# ADSP-2183xW_LPC register map
Vendor: Analog Devices; Series: ADSP-2183xW_LPC; File version: 3.0.3.517
CPU: 
Registers are 32-bit, read-write, reset 0x0 unless marked. A register's access mark holds for its fields unless they carry their own. Offsets are from the block's base; [hi:lo] are bit positions; {n}, {i} and the like mark numbered series; 'fields as' and 'values as' point back to an identical list.

## DAI0 — The Digital Audio Interface (DAIn) registers are used to configure DAI destinations for the DAI sources shown in the Group A - F Routing tables.
Base 0x310C9000
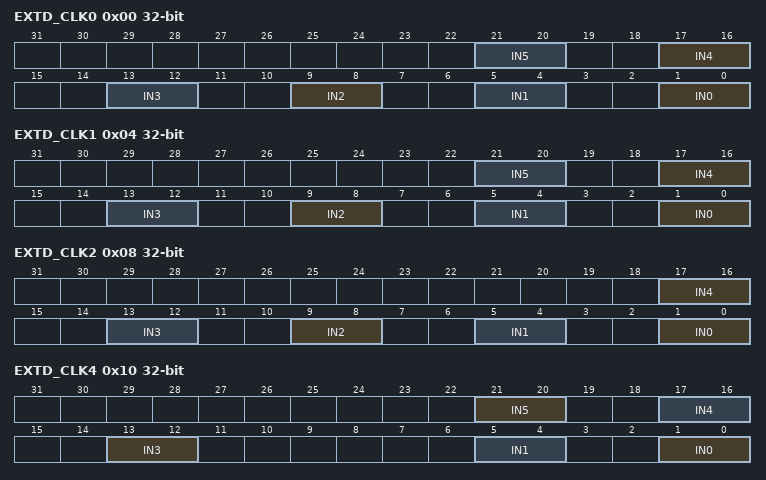
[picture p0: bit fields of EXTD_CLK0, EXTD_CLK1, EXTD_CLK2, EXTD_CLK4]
0x00 EXTD_CLK0 — Extended Clock Routing Control Register 0
  [4n+1:4n] IN{n} range 0x00000000..0x00000003 (n=0..5) — Extended Input Clock {n}
0x04 EXTD_CLK1 — Extended Clock Routing Control Register 1
  fields as EXTD_CLK0
0x08 EXTD_CLK2 — Extended Clock Routing Control Register 2
  [4n+1:4n] IN{n} range 0x00000000..0x00000003 (n=0..4) — Extended Input Clock {n}
0x0C EXTD_CLK3 — Extended Clock Routing Control Register 3
  [21:20] IN5 range 0x00000000..0x00000003 — Extended Input Clock 0
0x10 EXTD_CLK4 — Extended Clock Routing Control Register 4
  [21:20] IN5 range 0x00000000..0x00000003 — Extended Input Clock 5
  [17:16] IN4 range 0x00000000..0x00000003 — Extended Input Clock 4
  [13:12] IN3 range 0x00000000..0x00000003 — Extended Input Clock 3
  [5:4] IN1 range 0x00000000..0x00000003 — Extended Input Clock 1
  [1:0] IN0 range 0x00000000..0x00000003 — Extended Input Clock 0
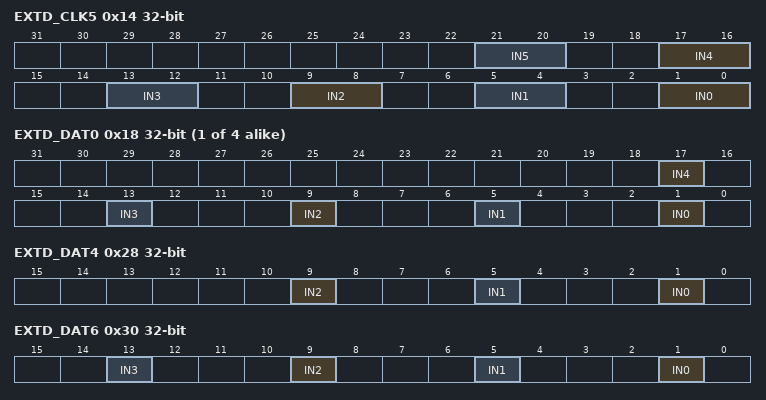
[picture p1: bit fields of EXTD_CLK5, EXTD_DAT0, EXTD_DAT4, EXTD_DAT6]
0x14 EXTD_CLK5 — Extended Clock Routing Control Register 5
  fields as EXTD_CLK0
{0x18+4i} EXTD_DAT{i} (i=0..3) — Extended Serial Data Routing Control Register {i}
  [4n+1] IN{n} range 0x00000000..0x00000001 (n=0..4) — Extended Input Data {n}
0x28 EXTD_DAT4 — Extended Serial Data Routing Control Register 4
  [9] IN2 range 0x00000000..0x00000001 — Extended Input Data 2
  [5] IN1 range 0x00000000..0x00000001 — Extended Input Data 1
  [1] IN0 range 0x00000000..0x00000001 — Extended Input Data 0
0x2C EXTD_DAT5 — Extended Serial Data Routing Control Register 5
  [17] IN4 range 0x00000000..0x00000001 — Extended Input Data 4
0x30 EXTD_DAT6 — Extended Serial Data Routing Control Register 6
  [4n+1] IN{n} range 0x00000000..0x00000001 (n=0..3) — Extended Input Data {n}
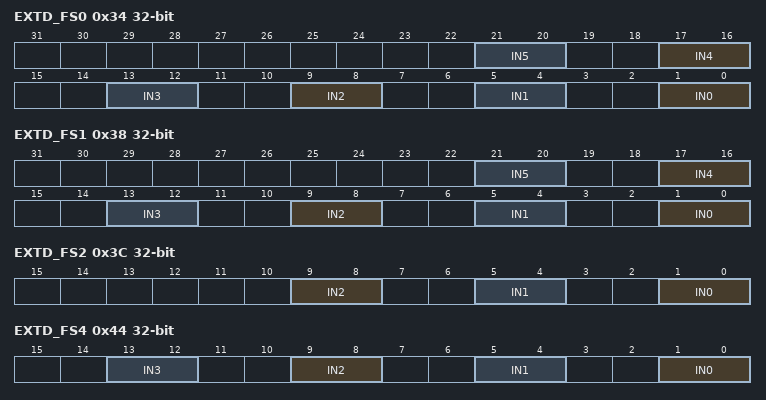
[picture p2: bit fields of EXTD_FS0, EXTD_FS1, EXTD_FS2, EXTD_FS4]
0x34 EXTD_FS0 — Extended Frame Sync Routing Control Register 0
  [4n+1:4n] IN{n} range 0x00000000..0x00000003 (n=0..5) — Extended Input Frame Sync {n}
0x38 EXTD_FS1 — Extended Frame Sync Routing Control Register 1
  fields as EXTD_FS0
0x3C EXTD_FS2 — Extended Frame Sync Routing Control Register 2
  [9:8] IN2 range 0x00000000..0x00000003 — Extended Input Frame Sync 2
  [5:4] IN1 range 0x00000000..0x00000003 — Extended Input Frame Sync 1
  [1:0] IN0 range 0x00000000..0x00000003 — Extended Input Frame Sync 0
0x44 EXTD_FS4 — Extended Frame Sync Routing Control Register 4
  [4n+1:4n] IN{n} range 0x00000000..0x00000003 (n=0..3) — Extended Input Frame Sync {n}
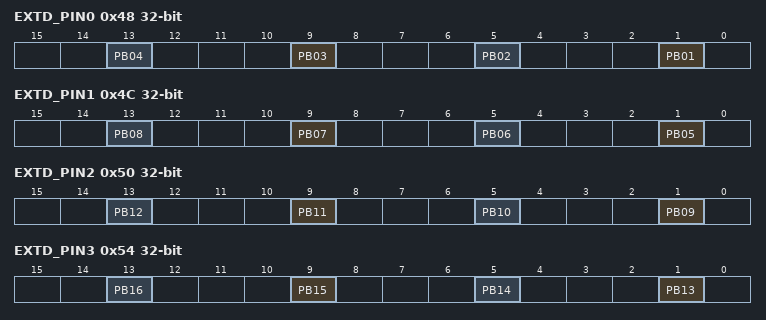
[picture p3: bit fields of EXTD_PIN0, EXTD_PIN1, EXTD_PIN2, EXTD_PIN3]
0x48 EXTD_PIN0 — Extended Pin Buffer Assignment Register 0
  [4n-3] PB{n:02} range 0x00000000..0x00000001 (n=1..4) — Extended Pin Buffer {n} Input
0x4C EXTD_PIN1 — Extended Pin Buffer Assignment Register 1
  [4n-19] PB{n:02} range 0x00000000..0x00000001 (n=5..8) — Extended Pin Buffer {n} Input
0x50 EXTD_PIN2 — Extended Pin Buffer Assignment Register 2
  [4n-35] PB{n:02} range 0x00000000..0x00000001 (n=9..12) — Extended Pin Buffer {n} Input
0x54 EXTD_PIN3 — Extended Pin Buffer Assignment Register 3
  [4n-51] PB{n} range 0x00000000..0x00000001 (n=13..16) — Extended Pin Buffer {n} Input
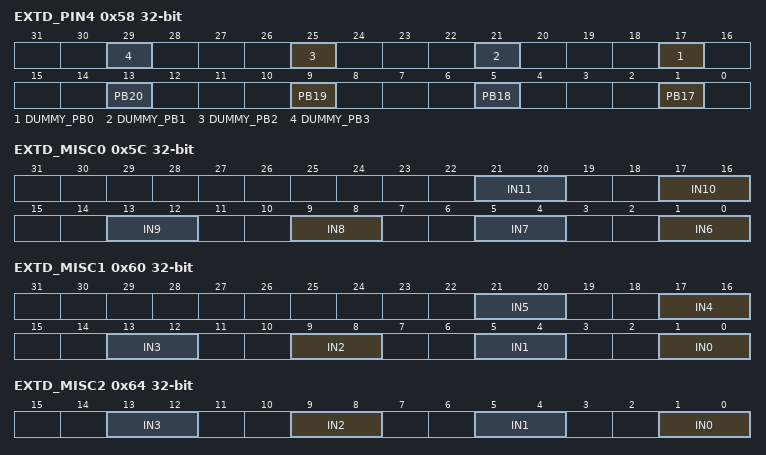
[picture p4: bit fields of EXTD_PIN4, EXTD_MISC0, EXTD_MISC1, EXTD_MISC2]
0x58 EXTD_PIN4 — Extended Pin Buffer Assignment Register 4
  [4n+17] DUMMY_PB{n} range 0x00000000..0x00000001 (n=0..3) — Extended Dummy Pin Buffer {n} Input
  [4n-67] PB{n} range 0x00000000..0x00000001 (n=17..20) — Extended Pin Buffer {n} Input
0x5C EXTD_MISC0 — Extended Miscellaneous Control Register 0
  [4n-23:4n-24] IN{n} range 0x00000000..0x00000003 (n=6..11) — Extended Input {n}
0x60 EXTD_MISC1 — Extended Miscellaneous Control Register 1
  [4n+1:4n] IN{n} range 0x00000000..0x00000003 (n=0..5) — Extended Input {n}
0x64 EXTD_MISC2 — Extended Miscellaneous Control Register 2
  [4n+1:4n] IN{n} range 0x00000000..0x00000003 (n=0..3) — Extended Input {n}
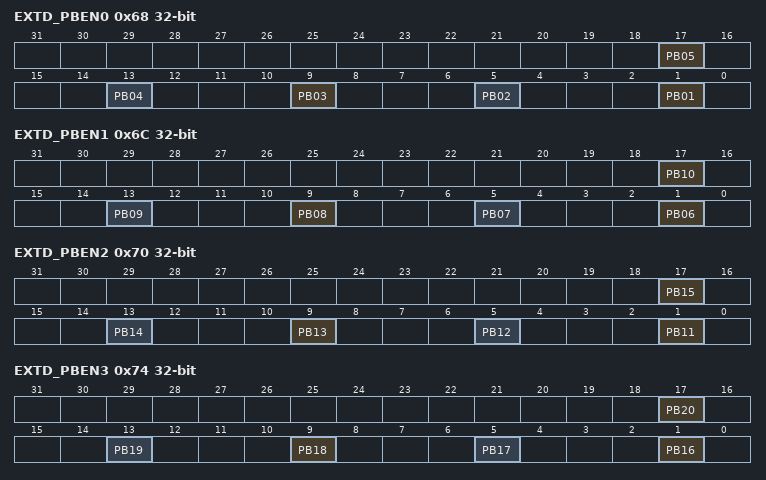
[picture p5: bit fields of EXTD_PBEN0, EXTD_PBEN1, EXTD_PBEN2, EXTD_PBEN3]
0x68 EXTD_PBEN0 — Extended Pin Buffer Enable Register 0
  [4n-3] PB{n:02} range 0x00000000..0x00000001 (n=1..5) — Extended Pin Buffer Enable {n}
0x6C EXTD_PBEN1 — Extended Pin Buffer Enable Register 1
  [4n-23] PB{n:02} range 0x00000000..0x00000001 (n=6..10) — Extended Pin Buffer Enable {n}
0x70 EXTD_PBEN2 — Extended Pin Buffer Enable Register 2
  [4n-43] PB{n} range 0x00000000..0x00000001 (n=11..15) — Extended Pin Buffer Enable {n}
0x74 EXTD_PBEN3 — Extended Pin Buffer Enable Register 3
  [4n-63] PB{n} range 0x00000000..0x00000001 (n=16..20) — Extended Pin Buffer Enable {n}
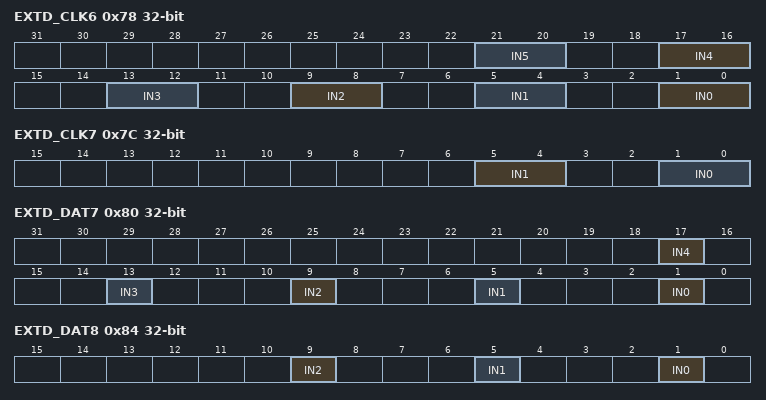
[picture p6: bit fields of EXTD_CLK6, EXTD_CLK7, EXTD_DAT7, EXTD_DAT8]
0x78 EXTD_CLK6 — Extended Clock Routing Control Register 6
  fields as EXTD_CLK0
0x7C EXTD_CLK7 — Extended Clock Routing Control Register 7
  [5:4] IN1 range 0x00000000..0x00000003 — Extended Input Clock 1
  [1:0] IN0 range 0x00000000..0x00000003 — Extended Input Clock 0
0x80 EXTD_DAT7 — Extended Serial Data Routing Control Register 7
  fields as EXTD_DAT0
0x84 EXTD_DAT8 — Extended Serial Data Routing Control Register 8
  fields as EXTD_DAT4
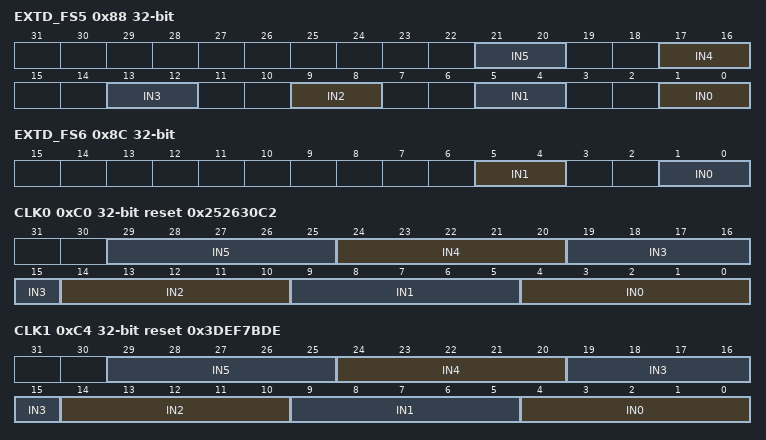
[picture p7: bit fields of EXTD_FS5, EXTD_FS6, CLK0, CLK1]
0x88 EXTD_FS5 — Extended Frame Sync Routing Control Register 5
  fields as EXTD_FS0
0x8C EXTD_FS6 — Extended Frame Sync Routing Control Register 6
  [5:4] IN1 range 0x00000000..0x00000003 — Extended Input Frame Sync 1
  [1:0] IN0 range 0x00000000..0x00000003 — Extended Input Frame Sync 0
0x9C DAI_MISC_CTL — DAI MISC Control Register
  [0] DUMMY_PAD_EN range 0x00000000..0x00000001 — Programmable Dummy Pad Enable
0xC0 CLK0 reset 0x252630C2 — Clock Routing Control Register 0
  [5n+4:5n] IN{n} range 0x00000000..0x0000001F (n=0..5) — Input Clock {n}
0xC4 CLK1 reset 0x3DEF7BDE — Clock Routing Control Register 1
  fields as CLK0
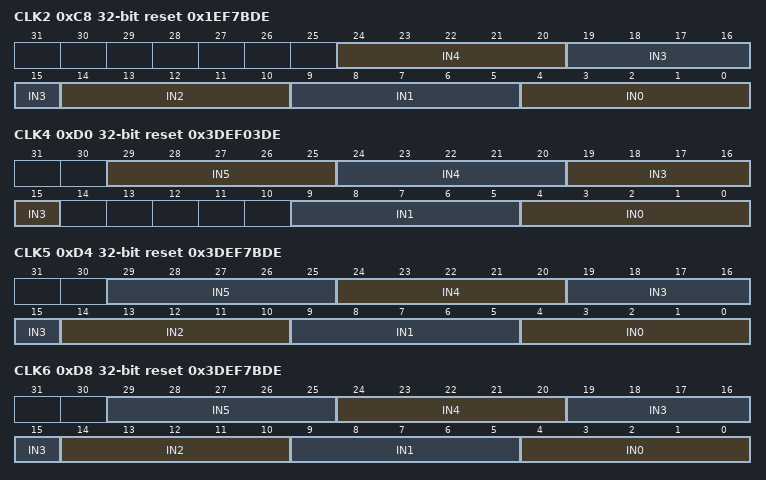
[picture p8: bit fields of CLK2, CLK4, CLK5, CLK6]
0xC8 CLK2 reset 0x1EF7BDE — Clock Routing Control Register 2
  [5n+4:5n] IN{n} range 0x00000000..0x0000001F (n=0..4) — Input Clock {n}
0xCC CLK3 reset 0x3C000000 — Clock Routing Control Register 3
  [29:25] IN5 range 0x00000000..0x0000001F — Input Clock 5
0xD0 CLK4 reset 0x3DEF03DE — Clock Routing Control Register 4
  [29:25] IN5 range 0x00000000..0x0000001F — Input Clock 5
  [24:20] IN4 range 0x00000000..0x0000001F — Input Clock 4
  [19:15] IN3 range 0x00000000..0x0000001F — Input Clock 3
  [9:5] IN1 range 0x00000000..0x0000001F — Input Clock 1
  [4:0] IN0 range 0x00000000..0x0000001F — Input Clock 0
0xD4 CLK5 reset 0x3DEF7BDE — Clock Routing Control Register 5
  fields as CLK0
0xD8 CLK6 reset 0x3DEF7BDE — Clock Routing Control Register 6
  fields as CLK0
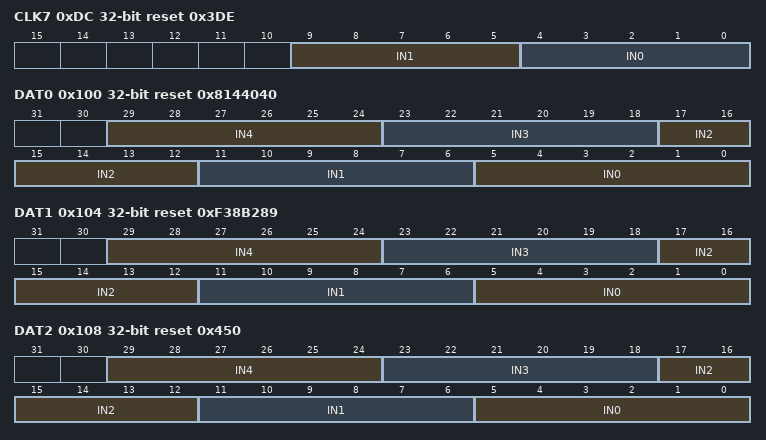
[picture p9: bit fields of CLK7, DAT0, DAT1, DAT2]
0xDC CLK7 reset 0x3DE — Clock Routing Control Register 7
  [9:5] IN1 range 0x00000000..0x0000001F — Input Clock 1
  [4:0] IN0 range 0x00000000..0x0000001F — Input Clock 0
0x100 DAT0 reset 0x8144040 — Serial Data Routing Control Register 0
  [6n+5:6n] IN{n} range 0x00000000..0x0000003F (n=0..4) — Input Data {n}
0x104 DAT1 reset 0xF38B289 — Serial Data Routing Control Register 1
  fields as DAT0
0x108 DAT2 reset 0x450 — Serial Data Routing Control Register 2
  fields as DAT0
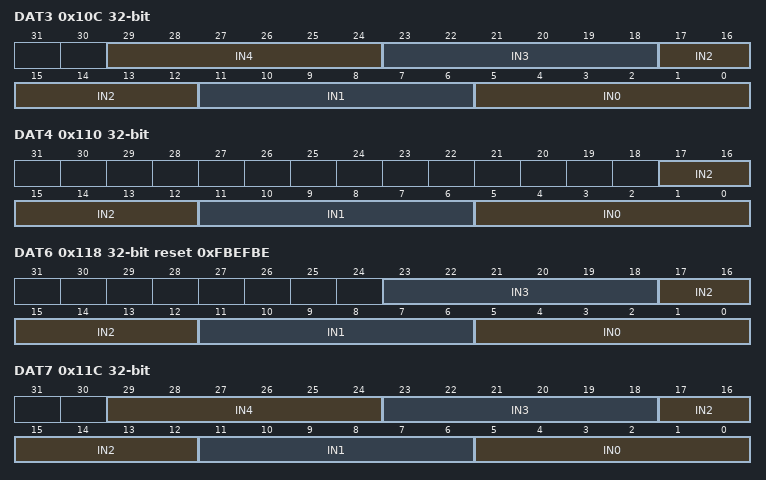
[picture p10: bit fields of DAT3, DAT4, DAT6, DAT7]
0x10C DAT3 — Serial Data Routing Control Register 3
  fields as DAT0
0x110 DAT4 — Serial Data Routing Control Register 4
  [17:12] IN2 range 0x00000000..0x0000003F — Input Data 2
  [11:6] IN1 range 0x00000000..0x0000003F — Input Data 1
  [5:0] IN0 range 0x00000000..0x0000003F — Input Data 0
0x114 DAT5 — Serial Data Routing Control Register 5
  [29:24] IN4 range 0x00000000..0x0000003F — Input Data 4
0x118 DAT6 reset 0xFBEFBE — Serial Data Routing Control Register 6
  [6n+5:6n] IN{n} range 0x00000000..0x0000003F (n=0..3) — Input Data {n}
0x11C DAT7 — Serial Data Routing Control Register 7
  fields as DAT0
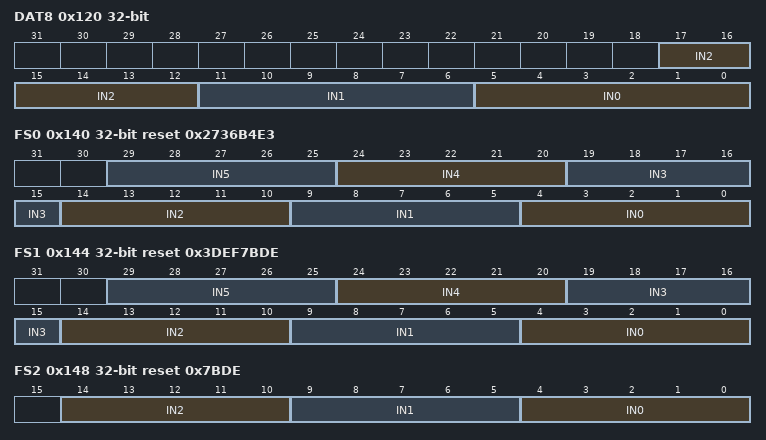
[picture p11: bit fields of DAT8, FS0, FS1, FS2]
0x120 DAT8 — Serial Data Routing Control Register 8
  fields as DAT4
0x140 FS0 reset 0x2736B4E3 — Frame Sync Routing Control Register 0
  [5n+4:5n] IN{n} range 0x00000000..0x0000001F (n=0..5) — Input Frame Sync {n}
0x144 FS1 reset 0x3DEF7BDE — Frame Sync Routing Control Register 1
  fields as FS0
0x148 FS2 reset 0x7BDE — Frame Sync Routing Control Register 2
  [14:10] IN2 range 0x00000000..0x0000001F — Input Frame Sync 2
  [9:5] IN1 range 0x00000000..0x0000001F — Input Frame Sync 1
  [4:0] IN0 range 0x00000000..0x0000001F — Input Frame Sync 0
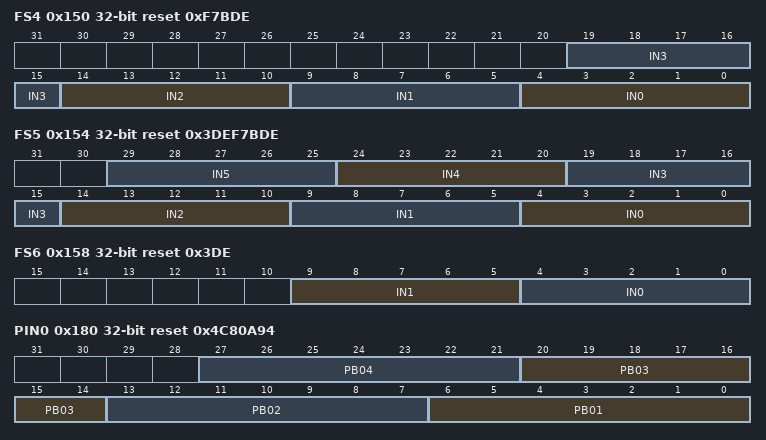
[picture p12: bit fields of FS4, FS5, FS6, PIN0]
0x150 FS4 reset 0xF7BDE — Frame Sync Routing Control Register 4
  [5n+4:5n] IN{n} range 0x00000000..0x0000001F (n=0..3) — Input Frame Sync {n}
0x154 FS5 reset 0x3DEF7BDE — Frame Sync Routing Control Register 5
  fields as FS0
0x158 FS6 reset 0x3DE — Frame Sync Routing Control Register 6
  [9:5] IN1 range 0x00000000..0x0000001F — Input Frame Sync 1
  [4:0] IN0 range 0x00000000..0x0000001F — Input Frame Sync 0
0x180 PIN0 reset 0x4C80A94 — Pin Buffer Assignment Register 0
  [7n-1:7n-7] PB{n:02} range 0x00000000..0x0000007F (n=1..4) — Pin Buffer {n} Input
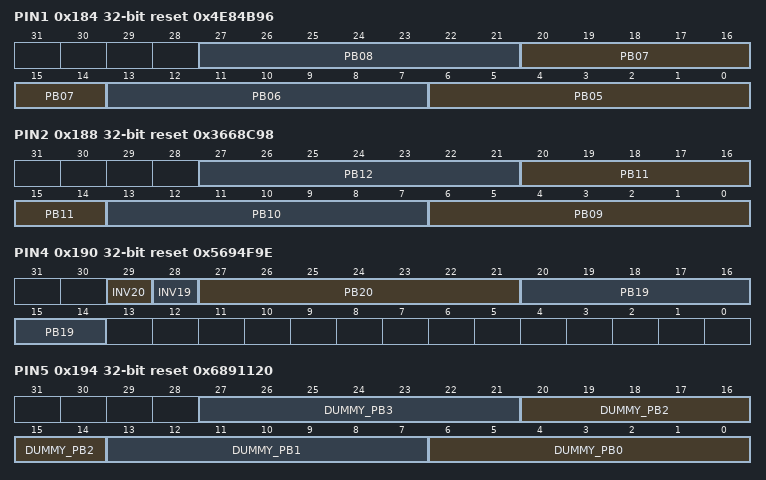
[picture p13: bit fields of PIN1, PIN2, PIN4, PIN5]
0x184 PIN1 reset 0x4E84B96 — Pin Buffer Assignment Register 1
  [7n-29:7n-35] PB{n:02} range 0x00000000..0x0000007F (n=5..8) — Pin Buffer {n} Input
0x188 PIN2 reset 0x3668C98 — Pin Buffer Assignment Register 2
  [7n-57:7n-63] PB{n:02} range 0x00000000..0x0000007F (n=9..12) — Pin Buffer {n} Input
0x190 PIN4 reset 0x5694F9E — Pin Buffer Assignment Register 4
  [29] INV20 range 0x00000000..0x00000001 — Pin Buffer 20 Invert
  [28] INV19 range 0x00000000..0x00000001 — Pin Buffer 19 Invert
  [27:21] PB20 range 0x00000000..0x0000007F — Pin Buffer 20 Input
  [20:14] PB19 range 0x00000000..0x0000007F — Pin Buffer 19 Input
0x194 PIN5 reset 0x6891120 — Dummy Pin Buffer Assignment Register
  [7n+6:7n] DUMMY_PB{n} range 0x00000000..0x0000007F (n=0..3) — Dummy Pin Buffer {n} Input
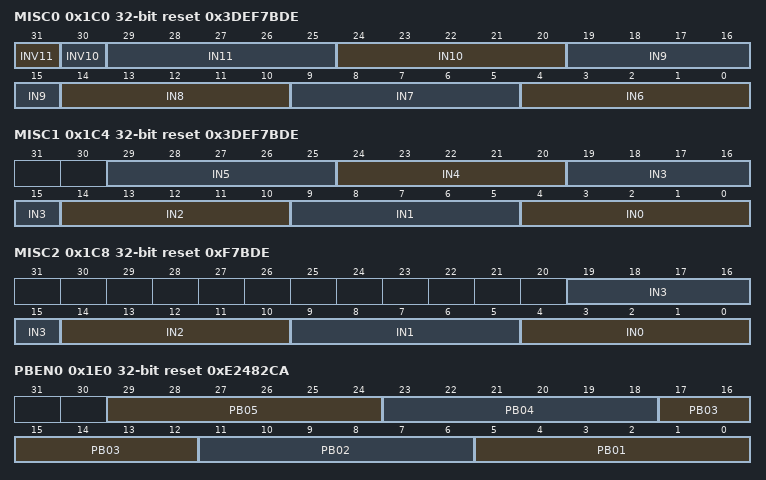
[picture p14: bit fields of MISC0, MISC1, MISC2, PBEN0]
0x1C0 MISC0 reset 0x3DEF7BDE — Miscellaneous Control Register 0
  [31] INV11 range 0x00000000..0x00000001 — Invert 11
  [30] INV10 range 0x00000000..0x00000001 — Invert 10
  [5n-26:5n-30] IN{n} range 0x00000000..0x0000001F (n=6..11) — Input {n}
0x1C4 MISC1 reset 0x3DEF7BDE — Miscellaneous Control Register 1
  [5n+4:5n] IN{n} range 0x00000000..0x0000001F (n=0..5) — Input {n}
0x1C8 MISC2 reset 0xF7BDE — Miscellaneous Control Register 1
  [5n+4:5n] IN{n} range 0x00000000..0x0000001F (n=0..3) — Input {n}
0x1E0 PBEN0 reset 0xE2482CA — Pin Buffer Enable Register 0
  [6n-1:6n-6] PB{n:02} range 0x00000000..0x0000003F (n=1..5) — Pin Buffer Enable {n}
0x1E4 PBEN1 reset 0x1348D30F — Pin Buffer Enable Register 1
  [6n-31:6n-36] PB{n:02} range 0x00000000..0x0000003F (n=6..10) — Pin Buffer Enable {n}
0x1E8 PBEN2 reset 0x1A5545D6 — Pin Buffer Enable Register 2
  [11:6] PB12 range 0x00000000..0x0000003F — Pin Buffer Enable 12
  [5:0] PB11 range 0x00000000..0x0000003F — Pin Buffer Enable 11
0x1EC PBEN3 reset 0x1D71F79B — Pin Buffer Enable Register 3
  [29:24] PB20 range 0x00000000..0x0000003F — Pin Buffer Enable 20
  [23:18] PB19 range 0x00000000..0x0000003F — Pin Buffer Enable 19
0x200 IMSK_FE — Falling-Edge Interrupt Mask Register
  [n+22] MISCINT{n} range 0x00000000..0x00000001 (n=0..9) — Miscellaneous Interrupt {n}
  [n+18] SRC{n}MUTE range 0x00000000..0x00000001 (n=0..3)
  [n+10] SRC{n}MUTE range 0x00000000..0x00000001 (n=4..7)
  [7] RXCHSCH range 0x00000000..0x00000001 — SPDIF Rx Channel Status Change
  [4] RXNONAUDIO range 0x00000000..0x00000001 — Receive Non Audio
  [2] RXLOSSOFLOCK range 0x00000000..0x00000001 — Receive Loss of Lock
  [1] RXLOCK range 0x00000000..0x00000001 — Receive Lock
  [0] RXVALID range 0x00000000..0x00000001 — Receive Valid
0x204 IMSK_RE — Rising-Edge Interrupt Mask Register
  fields as IMSK_FE
0x210 IMSK_PRI — Core Interrupt Priority Assignment Register
  [n+22] MISCINT{n} range 0x00000000..0x00000001 (n=0..9) — Miscellaneous Interrupt {n}
  [n+18] SRC{n}MUTE range 0x00000000..0x00000001 (n=0..3)
  [n+10] SRC{n}MUTE range 0x00000000..0x00000001 (n=4..7)
  [7] RXCHSCH range 0x00000000..0x00000001 — SPDIF Rx Channel Status Change
  [4] RXNONAUDIO range 0x00000000..0x00000001 — Receiver Non-Audio
  [2] RXLOSSOFLOCK range 0x00000000..0x00000001 — Receive Loss of Lock
  [1] RXLOCK range 0x00000000..0x00000001 — Receive Lock
  [0] RXVALID range 0x00000000..0x00000001 — Receive Valid
0x220 IRPTL_H — High Priority Interrupt Latch Register
  [n+22] MISCINT{n} ro (n=0..9) — Miscellaneous Interrupt {n}
  [n+18] SRC{n}MUTE ro (n=0..3)
  [n+10] SRC{n}MUTE ro (n=4..7)
  [7] RXCHSCH ro — SPDIF Rx Channel Status Change Indication
  [4] RXNONAUDIO ro — Receive Non Audio
  [2] RXLOSSOFLOCK ro — Receive Loss of Lock
  [1] RXLOCK ro — Receive Lock
  [0] RXVALID ro — Receive Valid
0x224 IRPTL_L — Low Priority Interrupt Latch Register
  [n+22] MISCINT{n} ro (n=0..9) — Miscellaneous Interrupt {n}
  [n+18] SRC{n}MUTE ro (n=0..3)
  [n+10] SRC{n}MUTE ro (n=4..7)
  [7] RXCHSCH ro — SPDIF Rx Channel Status Change
  [4] RXNONAUDIO ro — Receive Non Audio
  [2] RXLOSSOFLOCK ro — Receive Loss of Lock
  [1] RXLOCK ro — Receive Lock
  [0] RXVALID ro — Receive Valid
0x230 IRPTL_HS — Shadow High Priority Interrupt Latch Register
  fields as IRPTL_L
0x234 IRPTL_LS — Shadow Low Priority Interrupt Latch Register
  [n+22] MISCINT{n} ro (n=0..9) — Miscellaneous Interrupt {n}
  [n+18] SRC{n}MUTE ro (n=0..3)
  [n+10] SRC{n}MUTE ro (n=4..7)
  [7] RXCHSCH ro — SPDIF Rx Channel Status Change
  [4] RXNONAUDIO ro — Receiver Non Audio
  [2] RXLOSSOFLOCK ro — Receive Emphasis Loss of Lock
  [1] RXLOCK ro — Receive Error Lock
  [0] RXVALID ro — Receive Valid
0x2E4 PIN_STAT — Pin Status Register
  [19] PB20 ro — Pin Buffer 20 Status
  [18] PB19 ro — Pin Buffer 19 Status
  [n-1] PB{n:02} ro (n=1..12) — Pin Buffer {n:02} Status
0x2E8 GBL_SP_EN — Global SPORT Enable Register
  [4n+7] GBL_SP{n}B_SC_EN range 0x00000000..0x00000001 (n=0..3) — SPORT{n} B Secondary Channel Select
  [4n+6] GBL_SP{n}B_PC_EN range 0x00000000..0x00000001 (n=0..3) — SPORT{n} B Primary Channel Select
  [4n+5] GBL_SP{n}A_SC_EN range 0x00000000..0x00000001 (n=0..3) — SPORT{n} A Secondary Channel Select
  [4n+4] GBL_SP{n}A_PC_EN range 0x00000000..0x00000001 (n=0..3) — SPORT{n} A Primary Channel Select
  [3] GBL_SPEN_GRP1 range 0x00000000..0x00000001 — Group 1 SPORT Subgroup Select
  [2] GBL_SPEN_GRP0 range 0x00000000..0x00000001 — Group 0 SPORT Subgroup Select
  [1] GBL_SPEN_DAIX range 0x00000000..0x00000001 — DAI SPORTs Enable
  [0] GBL_SP_EN range 0x00000000..0x00000001 — Global SPORTs Enable
0x2EC GBL_INT_EN — Global SPORT Interrupt Grouping Register
  [19] GRP1_TRG_EN range 0x00000000..0x00000001 — Group 1 Trigger Enable
  [18] GRP0_TRG_EN range 0x00000000..0x00000001 — Group 0 Trigger Enable
  [17] GRP1_INT_EN range 0x00000000..0x00000001 — Group 1 Interrupt Enable
  [16] GRP0_INT_EN range 0x00000000..0x00000001 — Group 0 Interrupt Enable
  [2n+9] GRP1_SP{n}BINT_EN range 0x00000000..0x00000001 (n=0..3) — SP{n}B Interrupt/Trigger Group 1 Enable
  [2n+8] GRP1_SP{n}AINT_EN range 0x00000000..0x00000001 (n=0..3) — SP{n}A Interrupt/Trigger Group 1 Enable
  [2n+1] GRP0_SP{n}BINT_EN range 0x00000000..0x00000001 (n=0..3) — SP{n}B Interrupt/Trigger Group 0 Enable
  [2n] GRP0_SP{n}AINT_EN range 0x00000000..0x00000001 (n=0..3) — SP{n}A Interrupt/Trigger Group 0 Enable
0x2F0 GBL_PCG_EN — Global PCG Enable Control Register
  [23] GBL_PCGH_FS_EN range 0x00000000..0x00000001 — PCG-H Frame Sync Enable
  [22] GBL_PCGH_CLK_EN range 0x00000000..0x00000001 — PCG-H Clock Enable
  [21] GBL_PCGG_FS_EN range 0x00000000..0x00000001 — PCG-G Frame Sync Enable
  [20] GBL_PCGG_CLK_EN range 0x00000000..0x00000001 — PCG-G Clock Enable
  [19] GBL_PCGD_FS_EN range 0x00000000..0x00000001 — PCG-D Frame Sync Enable
  [18] GBL_PCGD_CLK_EN range 0x00000000..0x00000001 — PCG-D Clock Enable
  [17] GBL_PCGC_FS_EN range 0x00000000..0x00000001 — PCG-C Frame Sync Enable
  [16] GBL_PCGC_CLK_EN range 0x00000000..0x00000001 — PCG-C Clock Enable
  [15] GBL_PCGF_FS_EN range 0x00000000..0x00000001 — PCG-F Frame Sync Enable
  [14] GBL_PCGF_CLK_EN range 0x00000000..0x00000001 — PCG-F Clock Enable
  [13] GBL_PCGE_FS_EN range 0x00000000..0x00000001 — PCG-E Frame Sync Enable
  [12] GBL_PCGE_CLK_EN range 0x00000000..0x00000001 — PCG-E Clock Enable
  [11] GBL_PCGB_FS_EN range 0x00000000..0x00000001 — PCG-B Frame Sync Enable
  [10] GBL_PCGB_CLK_EN range 0x00000000..0x00000001 — PCG-B Clock Enable
  [9] GBL_PCGA_FS_EN range 0x00000000..0x00000001 — PCG-A Frame Sync Enable
  [8] GBL_PCGA_CLK_EN range 0x00000000..0x00000001 — PCG-A Clock Enable
  [2] GBL_PCG_CDGH_EN range 0x00000000..0x00000001 — PCG C/D/G/H Enable
  [1] GBL_PCG_ABEF_EN range 0x00000000..0x00000001 — PCG A/B/E/F Enable
  [0] GBL_PCG_EN range 0x00000000..0x00000001 — Global PCG Enable

## DAI1 — The Digital Audio Interface (DAIn) registers are used to configure DAI destinations for the DAI sources shown in the Group A - F Routing tables.
Base 0x310CA000
Registers as DAI0, without GBL_PCG_EN.
